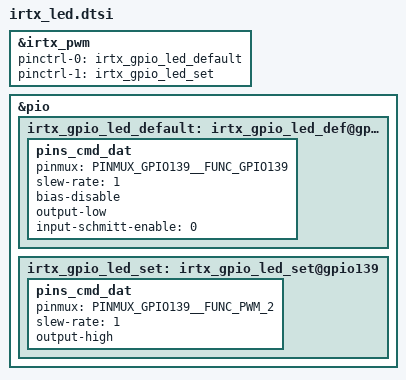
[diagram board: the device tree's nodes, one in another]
/* IRTX GPIO Start */
&irtx_pwm {
	pinctrl-names = "irtx_gpio_led_default", "irtx_gpio_led_set";
	pinctrl-0 = <&irtx_gpio_led_default>;
	pinctrl-1 = <&irtx_gpio_led_set>;
	status = "okay";
};
&pio {
	/* IRTX GPIO Settings -Start */
	/* default: GPIO0, output, high */
	irtx_gpio_led_default:irtx_gpio_led_def@gpio139 {
		pins_cmd_dat {
			pinmux = <PINMUX_GPIO139__FUNC_GPIO139>;
			slew-rate = <1>;
			bias-disable;
			output-low;
			input-schmitt-enable = <0>;
		};
	};

	irtx_gpio_led_set:irtx_gpio_led_set@gpio139 {
		pins_cmd_dat {
			pinmux = <PINMUX_GPIO139__FUNC_PWM_2>;
			slew-rate = <1>;
			output-high;
		};
	};
}; /* IRTX GPIO Settings -End */
